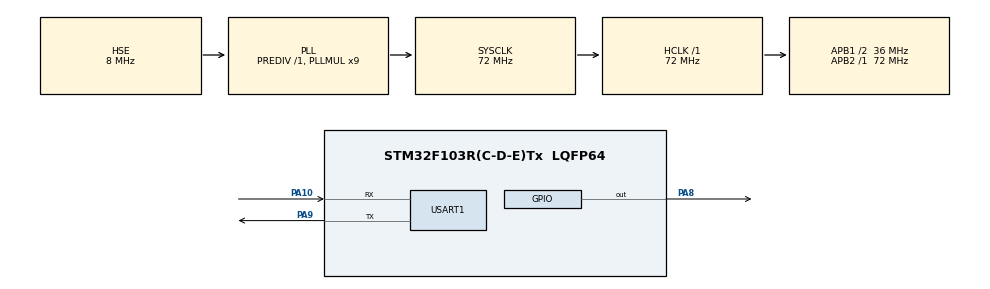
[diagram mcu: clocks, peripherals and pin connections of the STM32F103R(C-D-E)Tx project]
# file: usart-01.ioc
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Mcu.Family=STM32F1
RCC.PLLSourceVirtual=RCC_PLLSOURCE_HSE
PC15-OSC32_OUT.Mode=LSE-External-Oscillator
PD1-OSC_OUT.Mode=HSE-External-Oscillator
PA10.Mode=Asynchronous
PD0-OSC_IN.Signal=RCC_OSC_IN
RCC.APB1CLKDivider=RCC_HCLK_DIV2
PC14-OSC32_IN.Signal=RCC_OSC32_IN
RCC.SYSCLKSource=RCC_SYSCLKSOURCE_PLLCLK
ProjectManager.StackSize=0x400
PD1-OSC_OUT.Signal=RCC_OSC_OUT
PA13.Signal=SYS_JTMS-SWDIO
PA9.Mode=Asynchronous
ProjectManager.TargetToolchain=MDK-ARM V5
RCC.HCLKFreq_Value=72000000
RCC.APB2TimFreq_Value=72000000
PA9.Signal=USART1_TX
RCC.USBFreq_Value=72000000
PC15-OSC32_OUT.Signal=RCC_OSC32_OUT
RCC.AHBFreq_Value=72000000
PD0-OSC_IN.Mode=HSE-External-Oscillator
board=custom
RCC.PLLMUL=RCC_PLL_MUL9
RCC.APB2Freq_Value=72000000
PC14-OSC32_IN.Mode=LSE-External-Oscillator
PA14.Mode=Serial_Wire
PA8.Signal=GPIO_Output
PA13.Mode=Serial_Wire
Mcu.Name=STM32F103R(C-D-E)Tx
RCC.SYSCLKFreq_VALUE=72000000
Mcu.Package=LQFP64
USART1.VirtualMode=VM_ASYNC
PA10.Signal=USART1_RX
PA14.Signal=SYS_JTCK-SWCLK
ProjectManager.HeapSize=0x200
NVIC.PriorityGroup=NVIC_PRIORITYGROUP_4
RCC.APB1TimFreq_Value=72000000
NVIC.USART1_IRQn=true\:0\:0\:false\:false\:true\:true\:true
RCC.APB1Freq_Value=36000000

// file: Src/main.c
/* USER CODE BEGIN Header */
/**
  ******************************************************************************
  * @file           : main.c
  * @brief          : Main program body
  ******************************************************************************
  * @attention
  *
  * <h2><center>&copy; Copyright (c) 2020 STMicroelectronics.
  * All rights reserved.</center></h2>
  *
  * This software component is licensed by ST under BSD 3-Clause license,
  * the "License"; You may not use this file except in compliance with the
  * License. You may obtain a copy of the License at:
  *                        opensource.org/licenses/BSD-3-Clause
  *
  ******************************************************************************
  */
/* USER CODE END Header */

#include "main.h"
#include "usart.h"
#include "gpio.h"

void SystemClock_Config(void);

/* USER CODE BEGIN 0 */
#define LED1_ON() HAL_GPIO_WritePin(GPIOB,GPIO_PIN_9,GPIO_PIN_SET)
#define LED1_OFF() HAL_GPIO_WritePin(GPIOB,GPIO_PIN_9,GPIO_PIN_RESET)
#define LED2_ON() HAL_GPIO_WritePin(GPIOA,GPIO_PIN_8,GPIO_PIN_RESET)
#define LED2_OFF() HAL_GPIO_WritePin(GPIOA,GPIO_PIN_8,GPIO_PIN_SET)

uint8_t Tx_str1[] = "hello world!\r\n";
uint8_t Tx_str2[] = "LED1 Open!\r\n";
uint8_t Tx_str3[] = "LED1 Closed!\r\n";
uint8_t Rx_dat = 0;

void HAL_UART_RxCpltCallback(UART_HandleTypeDef *huart) {
    if (huart->Instance == USART1) {
        if (Rx_dat == 0xa1) {
            LED1_ON();

            LED2_ON();
            HAL_UART_Transmit(&huart1, Tx_str2, sizeof(Tx_str2), 10000);
            LED2_OFF();
            HAL_UART_Receive_IT(&huart1, &Rx_dat, 1);
        } else if (Rx_dat == 0xa2) {
            LED1_OFF();

            LED2_ON();
            HAL_UART_Transmit(&huart1, Tx_str3, sizeof(Tx_str3), 10000);
            LED2_OFF();
            HAL_UART_Receive_IT(&huart1, &Rx_dat, 1);
        }
    }
}
/* USER CODE END 0 */

int main(void)
{

  /* MCU Configuration--------------------------------------------------------*/

  /* Reset of all peripherals, Initializes the Flash interface and the Systick. */
  HAL_Init();

  /* Configure the system clock */
  SystemClock_Config();

  /* Initialize all configured peripherals */
  MX_GPIO_Init();
  MX_USART1_UART_Init();
  /* USER CODE BEGIN 2 */
//在mian()函数中添加以下代码：
    LED2_ON();
    HAL_UART_Transmit(&huart1, Tx_str1, sizeof(Tx_str1), 10000);    //向上位机发�?��?�hello world!�?
    LED2_OFF();
    HAL_UART_Receive_IT(&huart1, &Rx_dat, 1);                      //启动串口1接收上位�?1个字�?
  /* USER CODE END 2 */

  /* Infinite loop */
    while (1) {

    }
}

void SystemClock_Config(void)
{
  RCC_OscInitTypeDef RCC_OscInitStruct = {0};
  RCC_ClkInitTypeDef RCC_ClkInitStruct = {0};

  /** Initializes the CPU, AHB and APB busses clocks
  */
  RCC_OscInitStruct.OscillatorType = RCC_OSCILLATORTYPE_HSE;
  RCC_OscInitStruct.HSEState = RCC_HSE_ON;
  RCC_OscInitStruct.HSEPredivValue = RCC_HSE_PREDIV_DIV1;
  RCC_OscInitStruct.HSIState = RCC_HSI_ON;
  RCC_OscInitStruct.PLL.PLLState = RCC_PLL_ON;
  RCC_OscInitStruct.PLL.PLLSource = RCC_PLLSOURCE_HSE;
  RCC_OscInitStruct.PLL.PLLMUL = RCC_PLL_MUL9;
  if (HAL_RCC_OscConfig(&RCC_OscInitStruct) != HAL_OK)
  {
    Error_Handler();
  }
  /** Initializes the CPU, AHB and APB busses clocks
  */
  RCC_ClkInitStruct.ClockType = RCC_CLOCKTYPE_HCLK|RCC_CLOCKTYPE_SYSCLK
                              |RCC_CLOCKTYPE_PCLK1|RCC_CLOCKTYPE_PCLK2;
  RCC_ClkInitStruct.SYSCLKSource = RCC_SYSCLKSOURCE_PLLCLK;
  RCC_ClkInitStruct.AHBCLKDivider = RCC_SYSCLK_DIV1;
  RCC_ClkInitStruct.APB1CLKDivider = RCC_HCLK_DIV2;
  RCC_ClkInitStruct.APB2CLKDivider = RCC_HCLK_DIV1;

  if (HAL_RCC_ClockConfig(&RCC_ClkInitStruct, FLASH_LATENCY_2) != HAL_OK)
  {
    Error_Handler();
  }
}

void Error_Handler(void)
{
}

/************************ (C) COPYRIGHT STMicroelectronics *****END OF FILE****/
